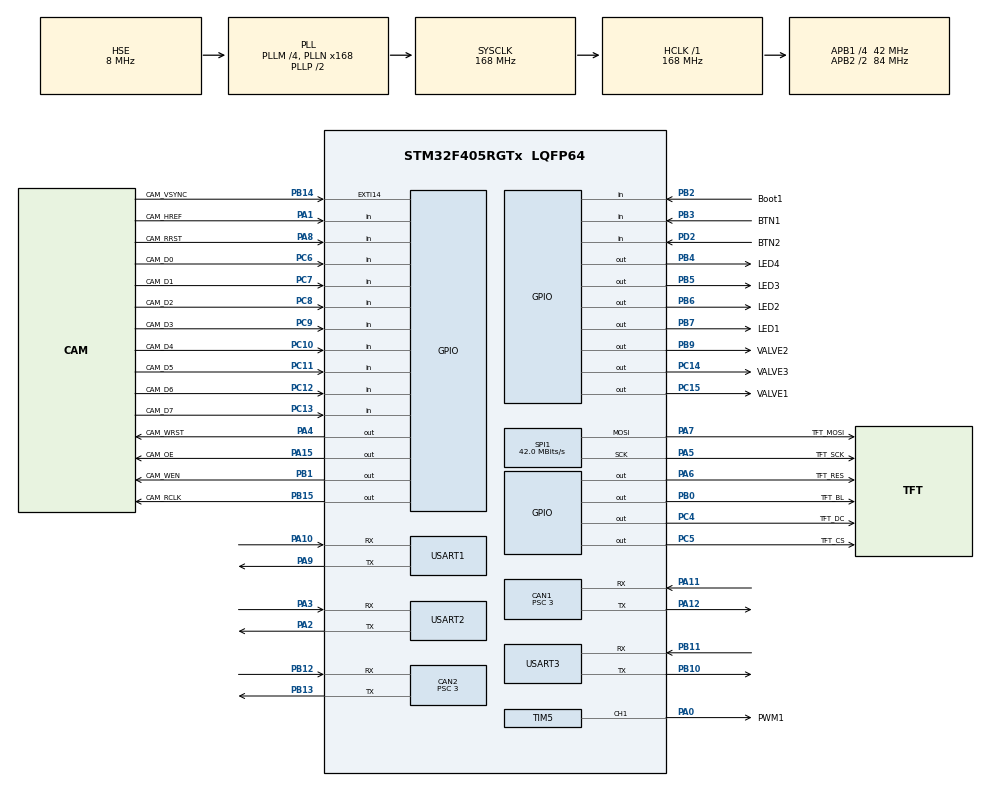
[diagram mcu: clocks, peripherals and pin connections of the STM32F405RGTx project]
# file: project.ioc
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CAN1.BS1=CAN_BS1_10TQ
CAN1.BS2=CAN_BS2_3TQ
CAN1.CalculateBaudRate=1000000
CAN1.CalculateTimeBit=1000
CAN1.CalculateTimeQuantum=71.42857142857143
CAN1.Prescaler=3
CAN2.BS1=CAN_BS1_10TQ
CAN2.BS2=CAN_BS2_3TQ
CAN2.CalculateBaudRate=1000000
CAN2.CalculateTimeBit=1000
CAN2.CalculateTimeQuantum=71.42857142857143
CAN2.Prescaler=3
Dma.Request0=SPI1_TX
Dma.SPI1_TX.0.Direction=DMA_MEMORY_TO_PERIPH
Dma.SPI1_TX.0.FIFOMode=DMA_FIFOMODE_ENABLE
Dma.SPI1_TX.0.FIFOThreshold=DMA_FIFO_THRESHOLD_FULL
Dma.SPI1_TX.0.Instance=DMA2_Stream3
Dma.SPI1_TX.0.MemBurst=DMA_MBURST_INC16
Dma.SPI1_TX.0.MemDataAlignment=DMA_MDATAALIGN_BYTE
Dma.SPI1_TX.0.MemInc=DMA_MINC_ENABLE
Dma.SPI1_TX.0.Mode=DMA_NORMAL
Dma.SPI1_TX.0.PeriphBurst=DMA_PBURST_SINGLE
Dma.SPI1_TX.0.PeriphDataAlignment=DMA_PDATAALIGN_BYTE
Dma.SPI1_TX.0.PeriphInc=DMA_PINC_DISABLE
Dma.SPI1_TX.0.Priority=DMA_PRIORITY_LOW
Mcu.Family=STM32F4
Mcu.Name=STM32F405RGTx
Mcu.Package=LQFP64
NVIC.DMA2_Stream3_IRQn=true\:0\:0\:false\:false\:true\:false\:true\:true
NVIC.EXTI15_10_IRQn=true\:0\:0\:false\:false\:true\:true\:true\:true
NVIC.PriorityGroup=NVIC_PRIORITYGROUP_4
NVIC.SPI1_IRQn=true\:0\:0\:false\:false\:true\:true\:true\:true
NVIC.TIM5_IRQn=true\:0\:0\:false\:false\:true\:true\:true\:true
NVIC.USART1_IRQn=true\:0\:0\:false\:false\:true\:true\:true\:true
NVIC.USART2_IRQn=true\:0\:0\:false\:false\:true\:true\:true\:true
NVIC.USART3_IRQn=true\:0\:0\:false\:false\:true\:true\:true\:true
PA0-WKUP.GPIO_Label=PWM1
PA0-WKUP.Signal=S_TIM5_CH1
PA1.GPIO_Label=CAM_HREF
PA1.Signal=GPIO_Input
PA10.Mode=Asynchronous
PA10.Signal=USART1_RX
PA11.Mode=CAN_Activate
PA11.Signal=CAN1_RX
PA12.Mode=CAN_Activate
PA12.Signal=CAN1_TX
PA13.Mode=Serial_Wire
PA13.Signal=SYS_JTMS-SWDIO
PA14.Mode=Serial_Wire
PA14.Signal=SYS_JTCK-SWCLK
PA15.GPIO_Label=CAM_OE
PA15.Signal=GPIO_Output
PA2.Mode=Asynchronous
PA2.Signal=USART2_TX
PA3.Mode=Asynchronous
PA3.Signal=USART2_RX
PA4.GPIO_Label=CAM_WRST
PA4.Signal=GPIO_Output
PA5.GPIO_Label=TFT_SCK
PA5.Mode=TX_Only_Simplex_Unidirect_Master
PA5.Signal=SPI1_SCK
PA6.GPIO_Label=TFT_RES
PA6.Signal=GPIO_Output
PA7.GPIO_Label=TFT_MOSI
PA7.Mode=TX_Only_Simplex_Unidirect_Master
PA7.Signal=SPI1_MOSI
PA8.GPIO_Label=CAM_RRST
PA8.Signal=GPIO_Input
PA9.Mode=Asynchronous
PA9.Signal=USART1_TX
PB0.GPIO_Label=TFT_BL
PB0.Signal=GPIO_Output
PB1.GPIO_Label=CAM_WEN
PB1.Signal=GPIO_Output
PB10.Mode=Asynchronous
PB10.Signal=USART3_TX
PB11.Mode=Asynchronous
PB11.Signal=USART3_RX
PB12.Mode=CAN_Activate
PB12.Signal=CAN2_RX
PB13.Mode=CAN_Activate
PB13.Signal=CAN2_TX
PB14.GPIO_Label=CAM_VSYNC
PB14.Signal=GPXTI14
PB15.GPIO_Label=CAM_RCLK
PB15.Signal=GPIO_Output
PB2.GPIO_Label=Boot1
PB2.Signal=GPIO_Input
PB3.GPIO_Label=BTN1
PB3.GPIO_PuPd=GPIO_PULLUP
PB3.Signal=GPIO_Input
PB4.GPIO_Label=LED4
PB4.Signal=GPIO_Output
PB5.GPIO_Label=LED3
PB5.Signal=GPIO_Output
PB6.GPIO_Label=LED2
PB6.Signal=GPIO_Output
PB7.GPIO_Label=LED1
PB7.Signal=GPIO_Output
PB9.GPIO_Label=VALVE2
PB9.GPIO_PuPd=GPIO_NOPULL
PB9.Signal=GPIO_Output
PC10.GPIO_Label=CAM_D4
PC10.Signal=GPIO_Input
PC11.GPIO_Label=CAM_D5
PC11.Signal=GPIO_Input
PC12.GPIO_Label=CAM_D6
PC12.GPIO_PuPd=GPIO_NOPULL
PC12.Signal=GPIO_Input
PC13-ANTI_TAMP.GPIO_Label=CAM_D7
PC13-ANTI_TAMP.Signal=GPIO_Input
PC14-OSC32_IN.GPIO_Label=VALVE3
PC14-OSC32_IN.GPIO_PuPd=GPIO_NOPULL
PC14-OSC32_IN.Signal=GPIO_Output
PC15-OSC32_OUT.GPIO_Label=VALVE1
PC15-OSC32_OUT.Signal=GPIO_Output
PC4.GPIO_Label=TFT_DC
PC4.Signal=GPIO_Output
PC5.GPIO_Label=TFT_CS
PC5.Signal=GPIO_Output
PC6.GPIO_Label=CAM_D0
PC6.Signal=GPIO_Input
PC7.GPIO_Label=CAM_D1
PC7.Signal=GPIO_Input
PC8.GPIO_Label=CAM_D2
PC8.Signal=GPIO_Input
PC9.GPIO_Label=CAM_D3
PC9.Signal=GPIO_Input
PD2.GPIO_Label=BTN2
PD2.GPIO_PuPd=GPIO_PULLUP
PD2.Signal=GPIO_Input
PH0-OSC_IN.Mode=HSE-External-Oscillator
PH0-OSC_IN.Signal=RCC_OSC_IN
PH1-OSC_OUT.Mode=HSE-External-Oscillator
PH1-OSC_OUT.Signal=RCC_OSC_OUT
ProjectManager.HeapSize=0x200
ProjectManager.StackSize=0x400
ProjectManager.TargetToolchain=Makefile
RCC.48MHZClocksFreq_Value=84000000
RCC.AHBFreq_Value=168000000
RCC.APB1CLKDivider=RCC_HCLK_DIV4
RCC.APB1Freq_Value=42000000
RCC.APB1TimFreq_Value=84000000
RCC.APB2CLKDivider=RCC_HCLK_DIV2
RCC.APB2Freq_Value=84000000
RCC.APB2TimFreq_Value=168000000
RCC.CortexFreq_Value=168000000
RCC.HCLKFreq_Value=168000000
RCC.HSE_VALUE=8000000
RCC.HSI_VALUE=16000000
RCC.LSE_VALUE=32768
RCC.PLLM=4
RCC.PLLN=168
RCC.PLLSourceVirtual=RCC_PLLSOURCE_HSE
RCC.SYSCLKFreq_VALUE=168000000
RCC.SYSCLKSource=RCC_SYSCLKSOURCE_PLLCLK
RCC.VCOOutputFreq_Value=336000000
SH.S_TIM5_CH1.0=TIM5_CH1,PWM Generation1 CH1
SPI1.CalculateBaudRate=42.0 MBits/s
SPI1.Direction=SPI_DIRECTION_2LINES
SPI1.Mode=SPI_MODE_MASTER
SPI1.VirtualType=VM_MASTER
TIM5.Channel-PWM\ Generation1\ CH1=TIM_CHANNEL_1
TIM5.OC1Preload_PWM=ENABLE
TIM5.Period=0
USART1.VirtualMode=VM_ASYNC
USART2.VirtualMode=VM_ASYNC
USART3.VirtualMode=VM_ASYNC
VP_TIM5_VS_ClockSourceINT.Mode=Internal
board=custom

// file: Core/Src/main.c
/* USER CODE BEGIN Header */
/**
 ******************************************************************************
 * @file           : main.c
 * @brief          : Main program body
 ******************************************************************************
 * @attention
 *
 * Copyright (c) 2023 STMicroelectronics.
 * All rights reserved.
 *
 * This software is licensed under terms that can be found in the LICENSE file
 * in the root directory of this software component.
 * If no LICENSE file comes with this software, it is provided AS-IS.
 *
 ******************************************************************************
 */
/* USER CODE END Header */
#include "main.h"
#include "can.h"
#include "dma.h"
#include "spi.h"
#include "tim.h"
#include "usart.h"
#include "gpio.h"

/* USER CODE BEGIN Includes */
#include "lcd/lcd.h"
#include "cpp_main.h"
/* USER CODE END Includes */

void SystemClock_Config(void);

int main(void)
{

    /* MCU Configuration--------------------------------------------------------*/

    /* Reset of all peripherals, Initializes the Flash interface and the Systick. */
    HAL_Init();

    /* Configure the system clock */
    SystemClock_Config();

    /* Initialize all configured peripherals */
    MX_GPIO_Init();
    MX_DMA_Init();
    MX_CAN2_Init();
    MX_SPI1_Init();
    MX_USART1_UART_Init();
    MX_CAN1_Init();
    MX_USART2_UART_Init();
    MX_TIM5_Init();
    MX_USART3_UART_Init();
    /* USER CODE BEGIN 2 */

    can_init(); // needs to be placed first or weird bugs
    // we turn off all the led first
    led_off(LED1);
    led_off(LED2);
    led_off(LED3);
    led_off(LED4);
    tft_init(PIN_ON_TOP, BLACK, WHITE, YELLOW, DARK_GREEN);
    HAL_GPIO_WritePin(GPIOC, GPIO_PIN_3, GPIO_PIN_SET);

    /* USER CODE END 2 */

    /* Infinite loop */

    /* USER CODE BEGIN 3 */
    return cpp_main();
    /* USER CODE END 3 */
}

void SystemClock_Config(void)
{
    RCC_OscInitTypeDef RCC_OscInitStruct = {0};
    RCC_ClkInitTypeDef RCC_ClkInitStruct = {0};

    /** Configure the main internal regulator output voltage
     */
    __HAL_RCC_PWR_CLK_ENABLE();
    __HAL_PWR_VOLTAGESCALING_CONFIG(PWR_REGULATOR_VOLTAGE_SCALE1);

    /** Initializes the RCC Oscillators according to the specified parameters
     * in the RCC_OscInitTypeDef structure.
     */
    RCC_OscInitStruct.OscillatorType = RCC_OSCILLATORTYPE_HSE;
    RCC_OscInitStruct.HSEState       = RCC_HSE_ON;
    RCC_OscInitStruct.PLL.PLLState   = RCC_PLL_ON;
    RCC_OscInitStruct.PLL.PLLSource  = RCC_PLLSOURCE_HSE;
    RCC_OscInitStruct.PLL.PLLM       = 4;
    RCC_OscInitStruct.PLL.PLLN       = 168;
    RCC_OscInitStruct.PLL.PLLP       = RCC_PLLP_DIV2;
    RCC_OscInitStruct.PLL.PLLQ       = 4;
    if (HAL_RCC_OscConfig(&RCC_OscInitStruct) != HAL_OK) {
        Error_Handler();
    }

    /** Initializes the CPU, AHB and APB buses clocks
     */
    RCC_ClkInitStruct.ClockType      = RCC_CLOCKTYPE_HCLK | RCC_CLOCKTYPE_SYSCLK | RCC_CLOCKTYPE_PCLK1 | RCC_CLOCKTYPE_PCLK2;
    RCC_ClkInitStruct.SYSCLKSource   = RCC_SYSCLKSOURCE_PLLCLK;
    RCC_ClkInitStruct.AHBCLKDivider  = RCC_SYSCLK_DIV1;
    RCC_ClkInitStruct.APB1CLKDivider = RCC_HCLK_DIV4;
    RCC_ClkInitStruct.APB2CLKDivider = RCC_HCLK_DIV2;

    if (HAL_RCC_ClockConfig(&RCC_ClkInitStruct, FLASH_LATENCY_5) != HAL_OK) {
        Error_Handler();
    }
}

void Error_Handler(void)
{
    __disable_irq();
    while (1) {
    }
}
